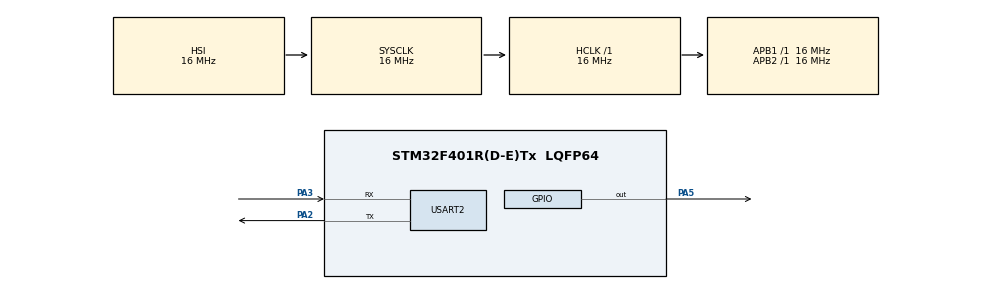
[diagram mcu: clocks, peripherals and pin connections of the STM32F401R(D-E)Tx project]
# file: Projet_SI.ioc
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FREERTOS.Tasks01=defaultTask,24,256,StartDefaultTask,Default,NULL,Dynamic,NULL,NULL;TaskAttaque,16,256,StartTaskAttaque,Default,NULL,Dynamic,NULL,NULL;TaskCritique,40,256,StartTaskCritique,Default,NULL,Dynamic,NULL,NULL
FREERTOS.configUSE_IDLE_HOOK=1
Mcu.Family=STM32F4
Mcu.Name=STM32F401R(D-E)Tx
Mcu.Package=LQFP64
NVIC.PriorityGroup=NVIC_PRIORITYGROUP_4
NVIC.TIM1_TRG_COM_TIM11_IRQn=true\:15\:0\:false\:false\:true\:false\:false\:true\:true
NVIC.TimeBase=TIM1_TRG_COM_TIM11_IRQn
NVIC.TimeBaseIP=TIM11
PA13.Mode=Serial_Wire
PA13.Signal=SYS_JTMS-SWDIO
PA14.Mode=Serial_Wire
PA14.Signal=SYS_JTCK-SWCLK
PA2.Mode=Asynchronous
PA2.Signal=USART2_TX
PA3.Mode=Asynchronous
PA3.Signal=USART2_RX
PA5.Signal=GPIO_Output
ProjectManager.HeapSize=0x200
ProjectManager.StackSize=0x400
ProjectManager.TargetToolchain=STM32CubeIDE
RCC.AHBFreq_Value=16000000
RCC.APB1Freq_Value=16000000
RCC.APB2Freq_Value=16000000
RCC.CortexFreq_Value=16000000
RCC.HSE_VALUE=25000000
RCC.HSI_VALUE=16000000
RCC.LSE_VALUE=32768
RCC.SYSCLKFreq_VALUE=16000000
RCC.VCOOutputFreq_Value=192000000
USART2.VirtualMode=VM_ASYNC
VP_FREERTOS_VS_CMSIS_V2.Mode=CMSIS_V2
VP_SYS_VS_tim11.Mode=TIM11
board=custom

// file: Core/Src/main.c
/* USER CODE BEGIN Header */
/**
  ******************************************************************************
  * @file           : main.c
  * @brief          : Main program body
  ******************************************************************************
  * @attention
  *
  * Copyright (c) 2026 STMicroelectronics.
  * All rights reserved.
  *
  * This software is licensed under terms that can be found in the LICENSE file
  * in the root directory of this software component.
  * If no LICENSE file comes with this software, it is provided AS-IS.
  *
  ******************************************************************************
  */
/* USER CODE END Header */
#include "main.h"
#include "cmsis_os.h"

/* USER CODE BEGIN Includes */
#include <stdio.h>
#include <string.h>
#include <stdint.h>
/* USER CODE END Includes */

/* USER CODE BEGIN PD */
#define CYCLES_TO_US(c)  ((c) / (SystemCoreClock / 1000000U))
#define CPU_SEUIL        50U     /* alerte si la charge CPU depasse 50 % */
/* USER CODE END PD */

UART_HandleTypeDef huart2;

/* Definitions for defaultTask */
osThreadId_t defaultTaskHandle;
const osThreadAttr_t defaultTask_attributes = {
  .name = "defaultTask",
  .stack_size = 256 * 4,
  .priority = (osPriority_t) osPriorityNormal,
};
/* Definitions for TaskAttaque */
osThreadId_t TaskAttaqueHandle;
const osThreadAttr_t TaskAttaque_attributes = {
  .name = "TaskAttaque",
  .stack_size = 256 * 4,
  .priority = (osPriority_t) osPriorityBelowNormal,
};
/* Definitions for TaskCritique */
osThreadId_t TaskCritiqueHandle;
const osThreadAttr_t TaskCritique_attributes = {
  .name = "TaskCritique",
  .stack_size = 256 * 4,
  .priority = (osPriority_t) osPriorityHigh,
};
/* USER CODE BEGIN PV */
volatile uint32_t max_jitter_us = 0;
volatile uint32_t deadline_miss = 0;
volatile uint32_t idle_count = 0;
/* USER CODE END PV */

void SystemClock_Config(void);
static void MX_GPIO_Init(void);
static void MX_USART2_UART_Init(void);
void StartDefaultTask(void *argument);
void StartTaskAttaque(void *argument);
void StartTaskCritique(void *argument);

/* USER CODE BEGIN 0 */
int _write(int fd, char *ptr, int len) {
    HAL_UART_Transmit(&huart2, (uint8_t*)ptr, len, HAL_MAX_DELAY);
    return len;
}

static inline void dwt_init(void) {
    CoreDebug->DEMCR |= CoreDebug_DEMCR_TRCENA_Msk;
    DWT->CYCCNT = 0;
    DWT->CTRL |= DWT_CTRL_CYCCNTENA_Msk;
}
/* USER CODE END 0 */

int main(void)
{

  /* MCU Configuration--------------------------------------------------------*/

  /* Reset of all peripherals, Initializes the Flash interface and the Systick. */
  HAL_Init();

  /* Configure the system clock */
  SystemClock_Config();

  /* Initialize all configured peripherals */
  MX_GPIO_Init();
  MX_USART2_UART_Init();
  /* USER CODE BEGIN 2 */
  dwt_init();

  /* Bouton bleu B1 = PC13 (entree) */
  __HAL_RCC_GPIOC_CLK_ENABLE();
  GPIO_InitTypeDef btn = {0};
  btn.Pin = GPIO_PIN_13;
  btn.Mode = GPIO_MODE_INPUT;
  btn.Pull = GPIO_NOPULL;
  HAL_GPIO_Init(GPIOC, &btn);
  /* USER CODE END 2 */

  /* Init scheduler */
  osKernelInitialize();

  /* Create the thread(s) */
  /* creation of defaultTask */
  defaultTaskHandle = osThreadNew(StartDefaultTask, NULL, &defaultTask_attributes);

  /* creation of TaskAttaque */
  TaskAttaqueHandle = osThreadNew(StartTaskAttaque, NULL, &TaskAttaque_attributes);

  /* creation of TaskCritique */
  TaskCritiqueHandle = osThreadNew(StartTaskCritique, NULL, &TaskCritique_attributes);

  /* Start scheduler */
  osKernelStart();

  /* We should never get here as control is now taken by the scheduler */

  /* Infinite loop */
  while (1)
  {

  }
}

void SystemClock_Config(void)
{
  RCC_OscInitTypeDef RCC_OscInitStruct = {0};
  RCC_ClkInitTypeDef RCC_ClkInitStruct = {0};

  /** Configure the main internal regulator output voltage
  */
  __HAL_RCC_PWR_CLK_ENABLE();
  __HAL_PWR_VOLTAGESCALING_CONFIG(PWR_REGULATOR_VOLTAGE_SCALE2);

  /** Initializes the RCC Oscillators according to the specified parameters
  * in the RCC_OscInitTypeDef structure.
  */
  RCC_OscInitStruct.OscillatorType = RCC_OSCILLATORTYPE_HSI;
  RCC_OscInitStruct.HSIState = RCC_HSI_ON;
  RCC_OscInitStruct.HSICalibrationValue = RCC_HSICALIBRATION_DEFAULT;
  RCC_OscInitStruct.PLL.PLLState = RCC_PLL_NONE;
  if (HAL_RCC_OscConfig(&RCC_OscInitStruct) != HAL_OK)
  {
    Error_Handler();
  }

  /** Initializes the CPU, AHB and APB buses clocks
  */
  RCC_ClkInitStruct.ClockType = RCC_CLOCKTYPE_HCLK|RCC_CLOCKTYPE_SYSCLK
                              |RCC_CLOCKTYPE_PCLK1|RCC_CLOCKTYPE_PCLK2;
  RCC_ClkInitStruct.SYSCLKSource = RCC_SYSCLKSOURCE_HSI;
  RCC_ClkInitStruct.AHBCLKDivider = RCC_SYSCLK_DIV1;
  RCC_ClkInitStruct.APB1CLKDivider = RCC_HCLK_DIV1;
  RCC_ClkInitStruct.APB2CLKDivider = RCC_HCLK_DIV1;

  if (HAL_RCC_ClockConfig(&RCC_ClkInitStruct, FLASH_LATENCY_0) != HAL_OK)
  {
    Error_Handler();
  }
}

static void MX_USART2_UART_Init(void)
{

  huart2.Instance = USART2;
  huart2.Init.BaudRate = 115200;
  huart2.Init.WordLength = UART_WORDLENGTH_8B;
  huart2.Init.StopBits = UART_STOPBITS_1;
  huart2.Init.Parity = UART_PARITY_NONE;
  huart2.Init.Mode = UART_MODE_TX_RX;
  huart2.Init.HwFlowCtl = UART_HWCONTROL_NONE;
  huart2.Init.OverSampling = UART_OVERSAMPLING_16;
  if (HAL_UART_Init(&huart2) != HAL_OK)
  {
    Error_Handler();
  }

}

static void MX_GPIO_Init(void)
{
  GPIO_InitTypeDef GPIO_InitStruct = {0};

  /* GPIO Ports Clock Enable */
  __HAL_RCC_GPIOA_CLK_ENABLE();
  __HAL_RCC_GPIOB_CLK_ENABLE();

  /*Configure GPIO pin Output Level */
  HAL_GPIO_WritePin(GPIOA, GPIO_PIN_5, GPIO_PIN_RESET);
  HAL_GPIO_WritePin(GPIOB, GPIO_PIN_0, GPIO_PIN_RESET);

  /*Configure GPIO pin : PA5 (LED Verte LD2) */
  GPIO_InitStruct.Pin = GPIO_PIN_5;
  GPIO_InitStruct.Mode = GPIO_MODE_OUTPUT_PP;
  GPIO_InitStruct.Pull = GPIO_NOPULL;
  GPIO_InitStruct.Speed = GPIO_SPEED_FREQ_LOW;
  HAL_GPIO_Init(GPIOA, &GPIO_InitStruct);

  /*Configure GPIO pin : PB0 (Buzzer Alarme - Broche A3) */
  GPIO_InitStruct.Pin = GPIO_PIN_0;
  GPIO_InitStruct.Mode = GPIO_MODE_OUTPUT_PP;
  GPIO_InitStruct.Pull = GPIO_NOPULL;
  GPIO_InitStruct.Speed = GPIO_SPEED_FREQ_LOW;
  HAL_GPIO_Init(GPIOB, &GPIO_InitStruct);

}

/* USER CODE BEGIN 4 */
static void Buzzer_Beep(uint32_t duration_ms, uint32_t freq_hz)
{
  uint32_t half_period_cycles = SystemCoreClock / (freq_hz * 2U);
  uint32_t total_cycles = (freq_hz * duration_ms) / 1000U;
  for (uint32_t i = 0; i < total_cycles; i++)
  {
    HAL_GPIO_WritePin(GPIOB, GPIO_PIN_0, GPIO_PIN_SET);
    uint32_t t = DWT->CYCCNT;
    while ((DWT->CYCCNT - t) < half_period_cycles) {}

    HAL_GPIO_WritePin(GPIOB, GPIO_PIN_0, GPIO_PIN_RESET);
    t = DWT->CYCCNT;
    while ((DWT->CYCCNT - t) < half_period_cycles) {}
  }
}
/* USER CODE END 4 */

void StartDefaultTask(void *argument)
{
  /* USER CODE BEGIN 5 */
  /* Calibration : 1 s sans appuyer sur B1 pour mesurer le compteur "CPU libre" */
  osDelay(1000);
  uint32_t idle_ref = idle_count;
  if (idle_ref == 0) idle_ref = 1;
  uint32_t last_idle = idle_count;

  /* Infinite loop : surveillance chaque seconde */
  for(;;)
  {
    osDelay(1000);

    uint32_t now_idle = idle_count;
    uint32_t delta = now_idle - last_idle;
    last_idle = now_idle;

    uint32_t idle_pct = (uint32_t)(((uint64_t)delta * 100U) / idle_ref);
    if (idle_pct > 100U) idle_pct = 100U;
    uint32_t cpu = 100U - idle_pct;

    printf("cpu=%lu%%  idle=%lu  ref=%lu  jitter_max=%lu us  miss=%lu\r\n",
             (unsigned long)cpu,
             (unsigned long)idle_count,
             (unsigned long)idle_ref,
             (unsigned long)max_jitter_us,
             (unsigned long)deadline_miss);
    max_jitter_us = 0;

    if (cpu > CPU_SEUIL)
    {
      printf("ALERT,%lu\r\n", (unsigned long)cpu);
      Buzzer_Beep(400, 2000); /* Alarme sonore stridente (2000 Hz pendant 400 ms) */
    }
    else
    {
      HAL_GPIO_WritePin(GPIOB, GPIO_PIN_0, GPIO_PIN_RESET);
    }
  }
  /* USER CODE END 5 */
}

void StartTaskAttaque(void *argument)
{
  /* USER CODE BEGIN StartTaskAttaque */
  /* Infinite loop : surcharge CPU de 2 s quand on appuie sur le bouton bleu */
  for(;;)
  {
    if (HAL_GPIO_ReadPin(GPIOC, GPIO_PIN_13) == GPIO_PIN_RESET)
    {
      uint32_t t = HAL_GetTick();
      while (HAL_GetTick() - t < 2000) { __NOP(); }

      while (HAL_GPIO_ReadPin(GPIOC, GPIO_PIN_13) == GPIO_PIN_RESET)
      {
        osDelay(10);
      }
    }
    osDelay(20);
  }
  /* USER CODE END StartTaskAttaque */
}

void StartTaskCritique(void *argument)
{
  /* USER CODE BEGIN StartTaskCritique */
  TickType_t last = xTaskGetTickCount();
  uint32_t prev = DWT->CYCCNT;
  /* Infinite loop : periode de 10 ms, mesure du jitter */
  for(;;)
  {
    vTaskDelayUntil(&last, pdMS_TO_TICKS(10));

    uint32_t now = DWT->CYCCNT;
    uint32_t period_us = CYCLES_TO_US(now - prev);
    prev = now;

    uint32_t jitter = (period_us > 10000) ? (period_us - 10000) : (10000 - period_us);
    if (jitter > max_jitter_us) max_jitter_us = jitter;
    if (jitter > 500) deadline_miss++;

    HAL_GPIO_TogglePin(GPIOA, GPIO_PIN_5);
  }
  /* USER CODE END StartTaskCritique */
}

void HAL_TIM_PeriodElapsedCallback(TIM_HandleTypeDef *htim)
{
  if (htim->Instance == TIM11)
  {
    HAL_IncTick();
  }
}

void Error_Handler(void)
{
  __disable_irq();
  while (1)
  {
  }
}

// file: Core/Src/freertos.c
/* USER CODE BEGIN Header */
/**
  ******************************************************************************
  * File Name          : freertos.c
  * Description        : Code for freertos applications
  ******************************************************************************
  * @attention
  *
  * Copyright (c) 2026 STMicroelectronics.
  * All rights reserved.
  *
  * This software is licensed under terms that can be found in the LICENSE file
  * in the root directory of this software component.
  * If no LICENSE file comes with this software, it is provided AS-IS.
  *
  ******************************************************************************
  */
/* USER CODE END Header */

#include "FreeRTOS.h"
#include "task.h"
#include "main.h"

/* Hook prototypes */
void vApplicationIdleHook(void);

/* USER CODE BEGIN 2 */
void vApplicationIdleHook( void )
{
	{
	  extern volatile uint32_t idle_count;
	  idle_count++;
	}
}
/* USER CODE END 2 */
